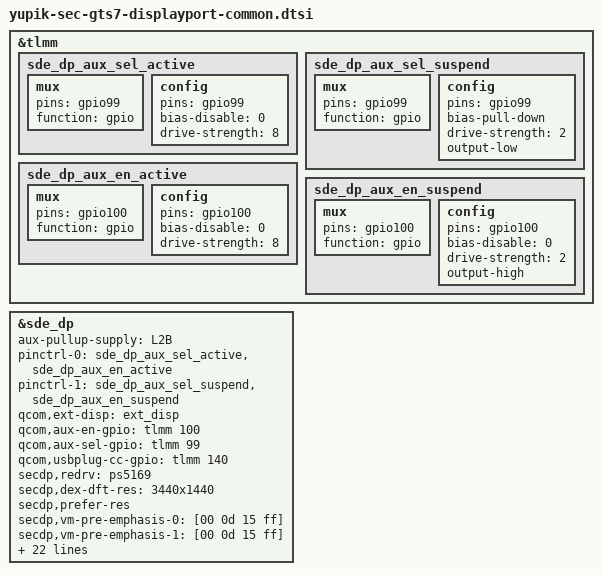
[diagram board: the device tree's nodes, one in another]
/* Copyright (c) 2016-2020, The Linux Foundation. All rights reserved.
 *
 * This program is free software; you can redistribute it and/or modify
 * it under the terms of the GNU General Public License version 2 and
 * only version 2 as published by the Free Software Foundation.
 *
 * This program is distributed in the hope that it will be useful,
 * but WITHOUT ANY WARRANTY; without even the implied warranty of
 * MERCHANTABILITY or FITNESS FOR A PARTICULAR PURPOSE.  See the
 * GNU General Public License for more details.
 */

/* SEC displayport setting */
&tlmm {
	/delete-node/ sde_dp_aux_active;
	/delete-node/ sde_dp_aux_suspend;
	/delete-node/ sde_dp_usbplug_cc_active;
	/delete-node/ sde_dp_usbplug_cc_suspend;

	sde_dp_aux_sel_active: sde_dp_aux_sel_active {
		mux {
			pins = "gpio99";
			function = "gpio";
		};

		config {
			pins = "gpio99";
			bias-disable = <0>; /* no pull */
			drive-strength = <8>;
		};
	};

	sde_dp_aux_sel_suspend: sde_dp_aux_sel_suspend {
		 mux {
			pins = "gpio99";
			function = "gpio";
		 };

		 config {
			pins = "gpio99";
			bias-pull-down;
			drive-strength = <2>;
			output-low;
		 };
	};

	sde_dp_aux_en_active: sde_dp_aux_en_active {
		mux {
			pins = "gpio100";
			function = "gpio";
		};

		config {
			pins = "gpio100";
			bias-disable = <0>; /* no pull */
			drive-strength = <8>;
		};
	};

	sde_dp_aux_en_suspend: sde_dp_aux_en_suspend {
		mux {
			pins = "gpio100";
			function = "gpio";
		};

		config {
			pins = "gpio100";
			bias-disable = <0>; /* no pull */
			drive-strength = <2>;
			output-high;
		};
	};
};

&sde_dp {
	/*vdda-1p2-supply = <&L22A>;*/
	/*vdda-0p9-supply = <&L16A>;*/
	aux-pullup-supply = <&L2B>;

	pinctrl-names = "mdss_dp_active", "mdss_dp_sleep";
	pinctrl-0 = <&sde_dp_aux_sel_active &sde_dp_aux_en_active>;
	pinctrl-1 = <&sde_dp_aux_sel_suspend &sde_dp_aux_en_suspend>;

	qcom,ext-disp = <&ext_disp>;

	qcom,aux-en-gpio = <&tlmm 100 0>;
	qcom,aux-sel-gpio = <&tlmm 99 0>;
	qcom,usbplug-cc-gpio = <&tlmm 140 0>;

	/*secdp,cc-dir-inv;*/
	/*secdp,aux-sel-inv;*/
	secdp,redrv = "ps5169";
	secdp,dex-dft-res = "3440x1440";
	secdp,prefer-res;

	secdp,vm-pre-emphasis-0   = [00 0d 15 ff];
	secdp,vm-pre-emphasis-1   = [00 0d 15 ff];
	secdp,vm-pre-emphasis-2   = [00 0c ff ff];
	secdp,vm-pre-emphasis-3   = [ff ff ff ff];

	secdp,vm-voltage-swing-0  = [07 0f 14 ff];
	secdp,vm-voltage-swing-1  = [11 1d 1f ff];
	secdp,vm-voltage-swing-2  = [18 1f ff ff];
	secdp,vm-voltage-swing-3  = [ff ff ff ff];

	secdp,pre-emp-hbr2-hbr3-0 = [00 0e 17 ff];
	secdp,pre-emp-hbr2-hbr3-1 = [00 0d 15 ff];
	secdp,pre-emp-hbr2-hbr3-2 = [00 0e ff ff];
	secdp,pre-emp-hbr2-hbr3-3 = [ff ff ff ff];

	secdp,swing-hbr2-hbr3-0   = [09 11 1b ff];
	secdp,swing-hbr2-hbr3-1   = [12 1a 1f ff];
	secdp,swing-hbr2-hbr3-2   = [1d 1f ff ff];
	secdp,swing-hbr2-hbr3-3   = [ff ff ff ff];

	secdp,pre-emp-hbr-rbr-0   = [00 0e 17 ff];
	secdp,pre-emp-hbr-rbr-1   = [00 0d 15 ff];
	secdp,pre-emp-hbr-rbr-2   = [00 0e ff ff];
	secdp,pre-emp-hbr-rbr-3   = [ff ff ff ff];

	secdp,swing-hbr-rbr-0     = [09 11 1b ff];
	secdp,swing-hbr-rbr-1     = [12 1a 1f ff];
	secdp,swing-hbr-rbr-2     = [1d 1f ff ff];
	secdp,swing-hbr-rbr-3     = [ff ff ff ff];
};
